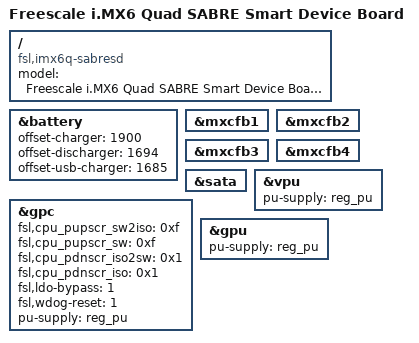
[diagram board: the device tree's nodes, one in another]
/*
 * Copyright 2012 Freescale Semiconductor, Inc.
 * Copyright 2011 Linaro Ltd.
 *
 * The code contained herein is licensed under the GNU General Public
 * License. You may obtain a copy of the GNU General Public License
 * Version 2 or later at the following locations:
 *
 * http://www.opensource.org/licenses/gpl-license.html
 * http://www.gnu.org/copyleft/gpl.html
 */

/dts-v1/;

#include "imx6q.dtsi"
#include "imx6qdl-sabresd.dtsi"

/ {
	model = "Freescale i.MX6 Quad SABRE Smart Device Board";
	compatible = "fsl,imx6q-sabresd", "fsl,imx6q";
};

&battery {
	offset-charger = <1900>;
	offset-discharger = <1694>;
	offset-usb-charger = <1685>;
};

&mxcfb1 {
	status = "okay";
};

&mxcfb2 {
	status = "okay";
};

&mxcfb3 {
	status = "okay";
};

&mxcfb4 {
	status = "okay";
};

&sata {
	status = "okay";
};

//add ben
&vpu {
        pu-supply = <&reg_pu>; /* ldo-bypass:use pu_dummy if VDDSOC share with VDDPU */
        status = "okay";
};
&gpc {
        fsl,cpu_pupscr_sw2iso = <0xf>;
        fsl,cpu_pupscr_sw = <0xf>;
        fsl,cpu_pdnscr_iso2sw = <0x1>;
        fsl,cpu_pdnscr_iso = <0x1>;
        fsl,ldo-bypass = <1>; /* use ldo-bypass, u-boot will check it and configure */
        fsl,wdog-reset = <1>; /* watchdog select of reset source */
        pu-supply = <&reg_pu>; /* ldo-bypass:use pu_dummy if VDDSOC share with VDDPU */
};

&gpu {
        pu-supply = <&reg_pu>; /* ldo-bypass:use pu_dummy if VDDSOC share with VDDPU */
};

